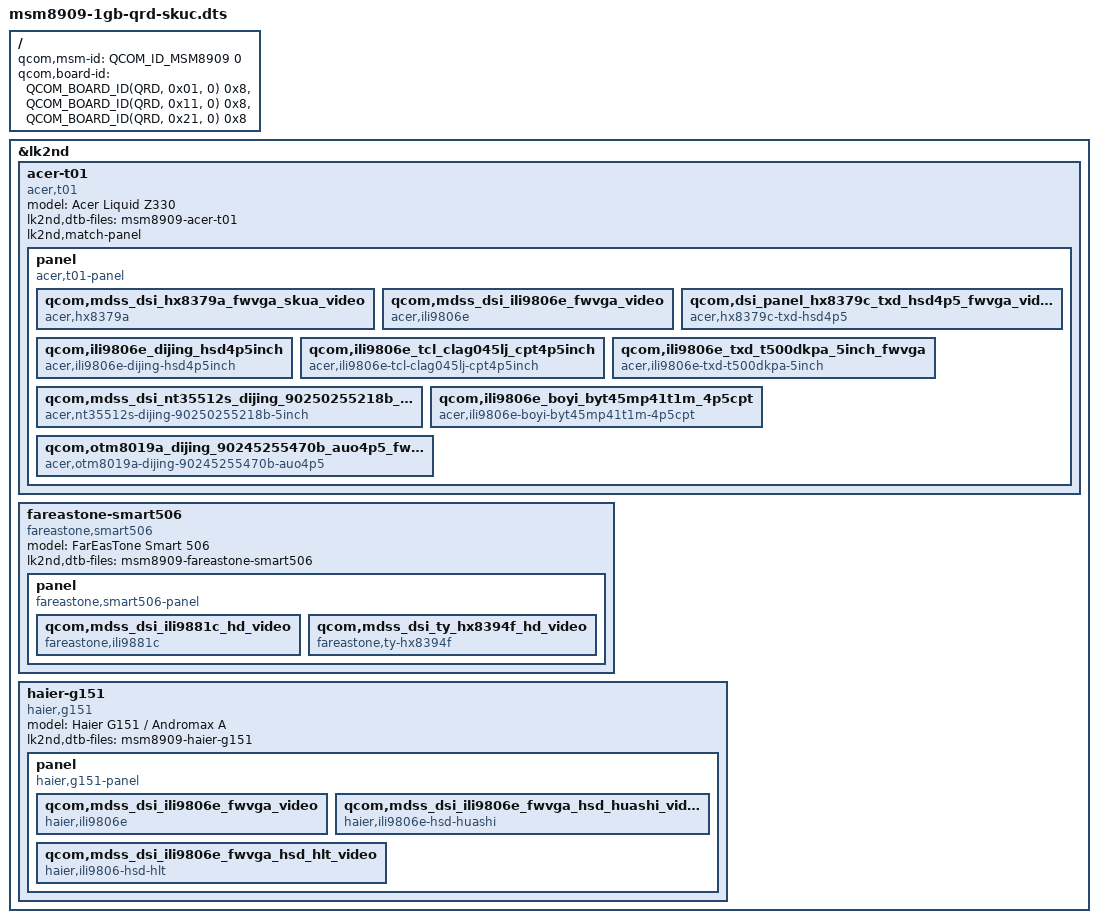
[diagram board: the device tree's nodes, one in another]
// SPDX-License-Identifier: BSD-3-Clause

#include <skeleton32.dtsi>
#include <lk2nd.dtsi>

/ {
	qcom,msm-id = <QCOM_ID_MSM8909 0>;
	qcom,board-id = <QCOM_BOARD_ID(QRD, 0x01, 0) 0x8>,
			<QCOM_BOARD_ID(QRD, 0x11, 0) 0x8>,
			<QCOM_BOARD_ID(QRD, 0x21, 0) 0x8>;
};

&lk2nd {
	acer-t01 {
		model = "Acer Liquid Z330";
		compatible = "acer,t01";

		lk2nd,dtb-files = "msm8909-acer-t01";
		lk2nd,match-panel;

		panel {
			compatible = "acer,t01-panel";

			qcom,mdss_dsi_hx8379a_fwvga_skua_video {
				compatible = "acer,hx8379a";
			};

			qcom,mdss_dsi_ili9806e_fwvga_video {
				compatible = "acer,ili9806e";
			};

			qcom,dsi_panel_hx8379c_txd_hsd4p5_fwvga_video {
				compatible = "acer,hx8379c-txd-hsd4p5";
			};

			qcom,ili9806e_dijing_hsd4p5inch {
				compatible = "acer,ili9806e-dijing-hsd4p5inch";
			};

			qcom,ili9806e_tcl_clag045lj_cpt4p5inch {
				compatible = "acer,ili9806e-tcl-clag045lj-cpt4p5inch";
			};

			qcom,ili9806e_txd_t500dkpa_5inch_fwvga {
				compatible = "acer,ili9806e-txd-t500dkpa-5inch";
			};

			qcom,mdss_dsi_nt35512s_dijing_90250255218b_5inch_fwvga {
				compatible = "acer,nt35512s-dijing-90250255218b-5inch";
			};

			qcom,ili9806e_boyi_byt45mp41t1m_4p5cpt {
				compatible = "acer,ili9806e-boyi-byt45mp41t1m-4p5cpt";
			};

			qcom,otm8019a_dijing_90245255470b_auo4p5_fwvga {
				compatible = "acer,otm8019a-dijing-90245255470b-auo4p5";
			};
		};
	};

	fareastone-smart506 {
		model = "FarEasTone Smart 506";
		compatible = "fareastone,smart506";

		/*
		 * NOTE:
		 * Due to some unknown reasons, the stock aboot firmware is
		 * incompatible with lk2nd. Use lk1st if possible.
		 *
		 * To build lk1st:
		 * make TOOLCHAIN_PREFIX=arm-none-eabi- \
		 * LK2ND_BUNDLE_DTB="msm8909-1gb-qrd-skuc.dtb" \
		 * LK2ND_COMPATIBLE="fareastone,smart506" lk1st-msm8909
		 */

		lk2nd,dtb-files = "msm8909-fareastone-smart506";

		panel {
			compatible = "fareastone,smart506-panel";

			qcom,mdss_dsi_ili9881c_hd_video {
				compatible = "fareastone,ili9881c";
			};

			qcom,mdss_dsi_ty_hx8394f_hd_video {
				compatible = "fareastone,ty-hx8394f";
			};
		};
	};

	haier-g151 {
		model = "Haier G151 / Andromax A";
		compatible = "haier,g151";

		/* NOTE
		 * Due to some unknown reasons, the stock aboot firmware is
		 * incompatible with lk2nd. Use lk1st if possible.
		 *
		 * To build lk1st:
		 * make TOOLCHAIN_PREFIX=arm-none-eabi- \
		 * LK2ND_BUNDLE_DTB="msm8909-1gb-qrd-skuc.dtb" \
		 * LK2ND_COMPATIBLE="haier,g151" \
		 * LK2ND_DISPLAY="<your_panel>" lk1st-msm8909
		 */

		lk2nd,dtb-files = "msm8909-haier-g151";

		panel {
			compatible = "haier,g151-panel";

			qcom,mdss_dsi_ili9806e_fwvga_video {
				compatible = "haier,ili9806e";
			};

			qcom,mdss_dsi_ili9806e_fwvga_hsd_huashi_video {
				compatible = "haier,ili9806e-hsd-huashi";
			};

			qcom,mdss_dsi_ili9806e_fwvga_hsd_hlt_video {
				compatible = "haier,ili9806-hsd-hlt";
			};
		};
	};
};
